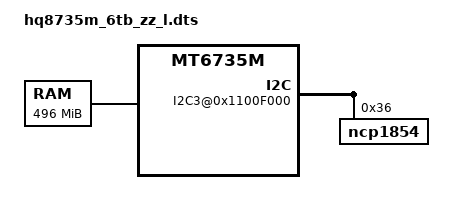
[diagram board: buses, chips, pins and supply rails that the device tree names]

/dts-v1/;

/include/ "mt6735m.dtsi"

/ {
  memory@00000000 {
		device_type = "memory";
		reg = <0 0x40000000 0 0x1F000000>;
	};

	bus {
		compatible = "simple-bus";
		#address-cells = <1>;
		#size-cells = <1>;
		ranges = <0 0 0 0xffffffff>;

		I2C3@0x1100F000 {
			ncp1854@36 {
				compatible = "ncp1854";
				reg = <0x36>;
			};
		};

		MTKFB@5e200000 {
			compatible = "mediatek,MTKFB";
			reg = <0x7F000000 0x1000000>;
		};

  };
};
